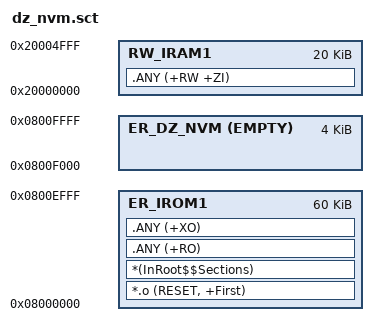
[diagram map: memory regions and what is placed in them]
; 由 tools/gen_ide_nvm.py 按 board.yaml mcu.nvm_kb=4 生成，勿手改。【未测】未在 Keil 里编译过。
; 保存区 ER_DZ_NVM 0x0800F000 长 0x00001000：EMPTY 域，不进 hex/axf 的加载数据，下载不会擦掉已存参数。
LR_IROM1 0x08000000 0x0000F000 {
  ER_IROM1 0x08000000 0x0000F000 {
   *.o (RESET, +First)
   *(InRoot$$Sections)
   .ANY (+RO)
   .ANY (+XO)
  }
  RW_IRAM1 0x20000000 0x00005000 {
   .ANY (+RW +ZI)
  }
}
LR_DZ_NVM 0x0800F000 0x00001000 {
  ER_DZ_NVM 0x0800F000 EMPTY 0x00001000 { }
}
